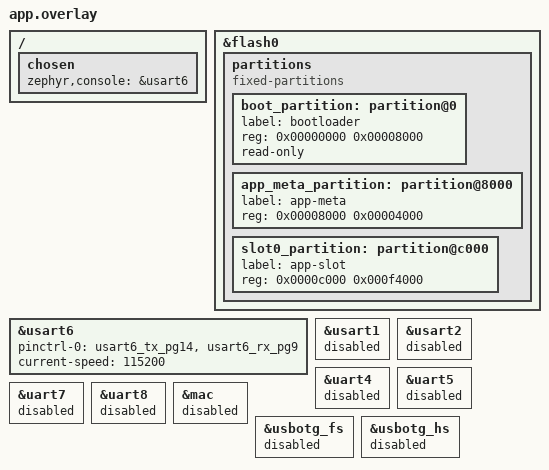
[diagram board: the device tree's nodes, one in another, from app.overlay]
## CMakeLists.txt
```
#
# CMakeLists.txt - Rust demo application on Zephyr (RZDEMO), NUCLEO-F767ZI
#
# Author:  Sandesh Ghimire <sandesh@soccentric.com>
# Date:    2026-11-04
# SRS:     SRS-RZEPHYR-F767 (RZCON-001..004, RZGEN-001..006)
#
# Freestanding Zephyr application built against $ZEPHYR_BASE in the
# stm32-dev-rust-zephyr container, without a west workspace.  The
# application is the Rust crate in this directory (Cargo.toml, src/lib.rs,
# src/app, src/platform, src/protocol), built by Zephyr's Rust module;
# platform/*.c is the small C layer for the driver APIs the Rust bindings do
# not cover yet.  The devicetree files live in boards/.
#   scripts/build.sh [clean]
#

cmake_minimum_required(VERSION 3.20.0)

set(BOARD nucleo_f767zi)
set(DTC_OVERLAY_FILE "${CMAKE_CURRENT_SOURCE_DIR}/boards/nucleo_f767zi.overlay")

# RZCON-002: Zephyr's Rust module is not part of the image's west filter, so
# add it explicitly (docker/Dockerfile installs it).
if(NOT DEFINED ENV{ZEPHYR_RUST_MODULE})
    message(FATAL_ERROR "ZEPHYR_RUST_MODULE is not set; build in the stm32-dev-rust-zephyr container")
endif()
list(APPEND ZEPHYR_EXTRA_MODULES "$ENV{ZEPHYR_RUST_MODULE}")

# --- Version and build metadata (RZGEN-002) --------------------------------
file(STRINGS "${CMAKE_CURRENT_SOURCE_DIR}/VERSION" VERSION_LINES)
foreach(_line IN LISTS VERSION_LINES)
    if(_line MATCHES "^VERSION_MAJOR[ \t]*=[ \t]*([0-9]+)")
        set(APP_VERSION_MAJOR "${CMAKE_MATCH_1}")
    elseif(_line MATCHES "^VERSION_MINOR[ \t]*=[ \t]*([0-9]+)")
        set(APP_VERSION_MINOR "${CMAKE_MATCH_1}")
    elseif(_line MATCHES "^PATCHLEVEL[ \t]*=[ \t]*([0-9]+)")
        set(APP_VERSION_PATCH "${CMAKE_MATCH_1}")
    endif()
endforeach()
if(NOT DEFINED APP_VERSION_MAJOR)
    set(APP_VERSION_MAJOR 0)
endif()
if(NOT DEFINED APP_VERSION_MINOR)
    set(APP_VERSION_MINOR 1)
endif()
if(NOT DEFINED APP_VERSION_PATCH)
    set(APP_VERSION_PATCH 0)
endif()
set(APP_VERSION "${APP_VERSION_MAJOR}.${APP_VERSION_MINOR}.${APP_VERSION_PATCH}")
set(APP_FIRMWARE_NAME "rust-zephyr-app")

execute_process(COMMAND git -C "${CMAKE_CURRENT_SOURCE_DIR}" rev-parse HEAD
    OUTPUT_VARIABLE APP_GIT_COMMIT_FULL OUTPUT_STRIP_TRAILING_WHITESPACE ERROR_QUIET)
if(DEFINED ENV{SOURCE_DATE_EPOCH})
    set(APP_BUILD_TIMESTAMP "$ENV{SOURCE_DATE_EPOCH}")
else()
    string(TIMESTAMP APP_BUILD_TIMESTAMP "%s" UTC)
endif()

# The image's Zephyr tree has no .git; its version is recorded in
# /opt/zephyrproject/VERSION by docker/Dockerfile.zephyr.
if(NOT DEFINED BUILD_VERSION AND EXISTS "$ENV{ZEPHYR_BASE}/../VERSION")
    file(STRINGS "$ENV{ZEPHYR_BASE}/../VERSION" BUILD_VERSION LIMIT_COUNT 1)
endif()

find_package(Zephyr REQUIRED HINTS $ENV{ZEPHYR_BASE})
project(rust_zephyr_app LANGUAGES C)

# RZCON-003: the Rust crate (package "rustapp") becomes librustapp.a and
# provides rust_main(), called from the module's main.c.  dt-rust.yaml is a
# local copy of the module's devicetree augments with the STM32 flash
# controller added.
set(DT_AUGMENTS "${CMAKE_CURRENT_SOURCE_DIR}/boards/dt-rust.yaml" CACHE INTERNAL "")
rust_cargo_application()

target_sources(app PRIVATE platform/platform.c platform/debug_log.c)
target_include_directories(app PRIVATE "${CMAKE_CURRENT_SOURCE_DIR}/platform")

# --- Build products (RZGEN-001, RZGEN-002) ----------------------------------
find_package(Python3 COMPONENTS Interpreter REQUIRED)
get_filename_component(_compiler_dir "${CMAKE_C_COMPILER}" DIRECTORY)
find_program(SIZE_TOOL NAMES arm-zephyr-eabi-size arm-none-eabi-size
    HINTS "${_compiler_dir}" REQUIRED)

add_custom_target(rust_zephyr_app_outputs ALL
    COMMAND ${CMAKE_COMMAND} -E copy
            "${CMAKE_BINARY_DIR}/zephyr/zephyr.elf"
            "${CMAKE_BINARY_DIR}/rust-zephyr-app.elf"
    COMMAND ${CMAKE_COMMAND} -E copy
            "${CMAKE_BINARY_DIR}/zephyr/zephyr.bin"
            "${CMAKE_BINARY_DIR}/rust-zephyr-app.bin"
    COMMAND ${CMAKE_COMMAND} -E copy
            "${CMAKE_BINARY_DIR}/zephyr/zephyr.hex"
            "${CMAKE_BINARY_DIR}/rust-zephyr-app.hex"
    COMMAND ${CMAKE_COMMAND} -E copy
            "${CMAKE_BINARY_DIR}/zephyr/zephyr.map"
            "${CMAKE_BINARY_DIR}/rust-zephyr-app.map"
    COMMAND ${Python3_EXECUTABLE} "${CMAKE_CURRENT_SOURCE_DIR}/scripts/mkimage.py"
            --input "${CMAKE_BINARY_DIR}/rust-zephyr-app.bin"
            --output "${CMAKE_BINARY_DIR}/rust-zephyr-app.img"
            --version "${APP_VERSION}"
            --commit "${APP_GIT_COMMIT_FULL}"
            --timestamp "${APP_BUILD_TIMESTAMP}"
            --name "${APP_FIRMWARE_NAME}"
    COMMAND ${Python3_EXECUTABLE} "${CMAKE_CURRENT_SOURCE_DIR}/scripts/check_footprint.py"
            --size-tool "${SIZE_TOOL}"
            --max-flash 131072
            --max-ram 65536
            "${CMAKE_BINARY_DIR}/rust-zephyr-app.elf"
    DEPENDS zephyr_final
    BYPRODUCTS
        "${CMAKE_BINARY_DIR}/rust-zephyr-app.elf"
        "${CMAKE_BINARY_DIR}/rust-zephyr-app.bin"
        "${CMAKE_BINARY_DIR}/rust-zephyr-app.hex"
        "${CMAKE_BINARY_DIR}/rust-zephyr-app.map"
        "${CMAKE_BINARY_DIR}/rust-zephyr-app.img"
    COMMENT "Copying rust-zephyr-app.* and generating the BOOT image file")
```

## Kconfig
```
#
# Kconfig - RZDEMO application options
#
# Author:  Sandesh Ghimire <sandesh@soccentric.com>
# Date:    2026-11-04
# Target:  NUCLEO-F767ZI
# SRS:     RZFN-004 (HLT-004)
#

mainmenu "Rust demo application on Zephyr (RZDEMO)"

config RZDEMO_FAIL_HEALTH
	bool "Force the pending-slot health check to fail"
	default n
	help
	  Build the equivalent of the C demo's DEMO_FAIL_HEALTH option.  A
	  pending slot never confirms, LD3 fast-blinks, and the watchdog is
	  stopped after 10 s so BOOT can count a failed trial and roll back.
	  build.rs exports it to Rust as cfg(CONFIG_RZDEMO_FAIL_HEALTH).

source "Kconfig.zephyr"
```

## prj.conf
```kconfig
# prj.conf - RZDEMO Kconfig
# Author: Sandesh Ghimire <sandesh@soccentric.com>
# SRS:    SRS-RZEPHYR-F767

# RZCON-003: the application is written in Rust (Zephyr's Rust module).
# No allocator: every buffer is static, as in the C demos.
CONFIG_RUST=y

# RZBT-001: run from the bootloader slot at 0x0800C000, 976 KB.
CONFIG_USE_DT_CODE_PARTITION=n
CONFIG_FLASH_LOAD_OFFSET=0xC000
CONFIG_FLASH_LOAD_SIZE=0xF4000

# RZRT-003: 1 kHz kernel tick.
CONFIG_SYS_CLOCK_TICKS_PER_SEC=1000

# RZGEN-003: caches on, as in the C demo.
CONFIG_CACHE_MANAGEMENT=y
CONFIG_ICACHE=y
CONFIG_DCACHE=y

# RZRT-006 / RZSAFE-004: MPU stack guards and assertions.
CONFIG_HW_STACK_PROTECTION=y
CONFIG_ASSERT=y

# RZGEN-006: no warnings in the C part either.
CONFIG_COMPILER_WARNINGS_AS_ERRORS=y

# LEDs, button and USART3.
CONFIG_GPIO=y
CONFIG_SERIAL=y
CONFIG_UART_INTERRUPT_DRIVEN=y
CONFIG_UART_USE_RUNTIME_CONFIGURE=y

# RZCON-005: USART3 carries HWLINK only.  RZDBG-001: console and log output
# go to USART6 instead (chosen zephyr,console in boards/nucleo_f767zi.overlay).
CONFIG_CONSOLE=y
CONFIG_UART_CONSOLE=y
CONFIG_PRINTK=y

# RZDBG-002: deferred logging, so no thread waits on the debug UART;
# RZDBG-003: platform/debug_log.c prints the family line format.
CONFIG_LOG=y
CONFIG_LOG_MODE_DEFERRED=y
CONFIG_LOG_BACKEND_UART=y
CONFIG_LOG_OUTPUT=y
CONFIG_LOG_CUSTOM_FORMAT_SUPPORT=y
CONFIG_LOG_BACKEND_UART_OUTPUT_CUSTOM=y
CONFIG_LOG_DEFAULT_LEVEL=3
CONFIG_LOG_BUFFER_SIZE=1024

# RZGEN-004: fatal errors reset the board.
CONFIG_REBOOT=y

# RZBT-006: Zephyr flash API for the CONFIRMED record.
CONFIG_FLASH=y

# RZRT-004: IWDG through the watchdog API.
CONFIG_WATCHDOG=y

# RZRT-005: stack high-water marks and thread names for Status.
CONFIG_INIT_STACKS=y
CONFIG_THREAD_STACK_INFO=y
CONFIG_THREAD_NAME=y

# rust_main() only starts the threads and returns.
CONFIG_MAIN_STACK_SIZE=4096
CONFIG_BOOT_BANNER=n
```

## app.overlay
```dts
/*
 * app.overlay - NUCLEO-F767ZI flash layout for the project A/B bootloader
 *
 * Author:  Sandesh Ghimire <sandesh@soccentric.com>
 * Date:    2026-11-03
 * Target:  NUCLEO-F767ZI
 * SRS:     ZBT-001, ZBT-006, ZSAFE-001/003
 *
 * The board devicetree describes an MCUboot-style layout.  ZDEMO uses the
 * project bootloader layout instead (SRS-BOOT-F767 section 3):
 *
 *   0x08000000  bootloader, sectors 0-1, 32 KB, read-only
 *   0x08008000  metadata, sector 2, 16 KB
 *   0x0800C000  application slot, sectors 3-11, 976 KB
 *
 * Bank swapping maps either bank at 0x08000000, so the same overlay and
 * image work for slot A and slot B.
 */

/delete-node/ &boot_partition;
/delete-node/ &storage_partition;
/delete-node/ &slot0_partition;
/delete-node/ &slot1_partition;
/delete-node/ &scratch_partition;

&flash0 {
	partitions {
		compatible = "fixed-partitions";
		#address-cells = <1>;
		#size-cells = <1>;

		boot_partition: partition@0 {
			label = "bootloader";
			reg = <0x00000000 0x00008000>;
			read-only;
		};

		app_meta_partition: partition@8000 {
			label = "app-meta";
			reg = <0x00008000 0x00004000>;
		};

		slot0_partition: partition@c000 {
			label = "app-slot";
			reg = <0x0000c000 0x000f4000>;
		};
	};
};

/* RZDBG-001: console and log output on USART6 (PG14 = Arduino D1 TX,
 * PG9 = D0 RX), 115200 8N1.  HWLINK keeps USART3 to itself. */
/ {
	chosen {
		zephyr,console = &usart6;
	};
};

&usart6 {
	pinctrl-0 = <&usart6_tx_pg14 &usart6_rx_pg9>;
	pinctrl-names = "default";
	current-speed = <115200>;
	status = "okay";
};

/* ZSAFE-003: only the LEDs, B1, USART3 (HWLINK) and USART6 (debug) are
 * used. */
&usart1 {
	status = "disabled";
};

&usart2 {
	status = "disabled";
};

&uart4 {
	status = "disabled";
};

&uart5 {
	status = "disabled";
};

&uart7 {
	status = "disabled";
};

&uart8 {
	status = "disabled";
};

&mac {
	status = "disabled";
};

&usbotg_fs {
	status = "disabled";
};

&usbotg_hs {
	status = "disabled";
};
```

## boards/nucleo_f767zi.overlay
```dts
/*
 * nucleo_f767zi.overlay - NUCLEO-F767ZI flash layout for the project A/B bootloader
 *
 * Author:  Sandesh Ghimire <sandesh@soccentric.com>
 * Date:    2026-11-03
 * Target:  NUCLEO-F767ZI
 * SRS:     ZBT-001, ZBT-006, ZSAFE-001/003
 *
 * The board devicetree describes an MCUboot-style layout.  ZDEMO uses the
 * project bootloader layout instead (SRS-BOOT-F767 section 3):
 *
 *   0x08000000  bootloader, sectors 0-1, 32 KB, read-only
 *   0x08008000  metadata, sector 2, 16 KB
 *   0x0800C000  application slot, sectors 3-11, 976 KB
 *
 * Bank swapping maps either bank at 0x08000000, so the same overlay and
 * image work for slot A and slot B.
 */

/delete-node/ &boot_partition;
/delete-node/ &storage_partition;
/delete-node/ &slot0_partition;
/delete-node/ &slot1_partition;
/delete-node/ &scratch_partition;

&flash0 {
	partitions {
		compatible = "fixed-partitions";
		#address-cells = <1>;
		#size-cells = <1>;

		boot_partition: partition@0 {
			label = "bootloader";
			reg = <0x00000000 0x00008000>;
			read-only;
		};

		app_meta_partition: partition@8000 {
			label = "app-meta";
			reg = <0x00008000 0x00004000>;
		};

		slot0_partition: partition@c000 {
			label = "app-slot";
			reg = <0x0000c000 0x000f4000>;
		};
	};
};

/* RZDBG-001: console and log output on USART6 (PG14 = Arduino D1 TX,
 * PG9 = D0 RX), 115200 8N1.  HWLINK keeps USART3 to itself. */
/ {
	chosen {
		zephyr,console = &usart6;
	};
};

&usart6 {
	pinctrl-0 = <&usart6_tx_pg14 &usart6_rx_pg9>;
	pinctrl-names = "default";
	current-speed = <115200>;
	status = "okay";
};

/* ZSAFE-003: only the LEDs, B1, USART3 (HWLINK) and USART6 (debug) are
 * used. */
&usart1 {
	status = "disabled";
};

&usart2 {
	status = "disabled";
};

&uart4 {
	status = "disabled";
};

&uart5 {
	status = "disabled";
};

&uart7 {
	status = "disabled";
};

&uart8 {
	status = "disabled";
};

&mac {
	status = "disabled";
};

&usbotg_fs {
	status = "disabled";
};

&usbotg_hs {
	status = "disabled";
};
```

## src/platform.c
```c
/*
 * platform.c - C platform layer called from the Rust application
 *
 * Author:  Sandesh Ghimire <sandesh@soccentric.com>
 * Date:    2026-11-04
 * Target:  NUCLEO-F767ZI (Zephyr board nucleo_f767zi)
 * SRS:     RZCON-004, RZBT-002, RZBT-006, RZFN-003, RZRT-004, RZGEN-004
 *
 * Driver glue only: the Rust modules in src/ own the application logic.
 * The UART and fatal-error code follow the C Zephyr demo
 * (app-c-zephyr) so both builds behave the same.
 */

#include <soc.h>
#include <string.h>
#include <zephyr/arch/cpu.h>
#include <zephyr/arch/arm/arch.h>
#include <zephyr/device.h>
#include <zephyr/drivers/flash.h>
#include <zephyr/drivers/gpio.h>
#include <zephyr/drivers/uart.h>
#include <zephyr/drivers/watchdog.h>
#include <zephyr/fatal.h>
#include <zephyr/init.h>
#include <zephyr/kernel.h>
#include <zephyr/linker/sections.h>
#include <zephyr/storage/flash_map.h>
#include <zephyr/sys/reboot.h>
#include <zephyr/sys/ring_buffer.h>

#include "platform.h"

BUILD_ASSERT(CONFIG_FLASH_LOAD_OFFSET == 0xC000,
	     "RZBT-001: the application must be linked at 0x0800C000");
BUILD_ASSERT(CONFIG_FLASH_LOAD_SIZE == 0xF4000,
	     "RZBT-001: the application slot is 976 KB");

/* ---------------------------------------------------------------- fault */

#define FAULT_MAGIC      0x4641554CUL /* "FAUL" */
#define FAULT_REASON_MAX 8U           /* startup, the last reason */

enum {
	FAULT_NONE = 0,
	FAULT_HARDFAULT,
	FAULT_MEMMANAGE,
	FAULT_BUSFAULT,
	FAULT_USAGEFAULT,
	FAULT_ASSERT,
	FAULT_STACK_OVERFLOW,
	FAULT_MALLOC_FAILED,
	FAULT_STARTUP
};

struct fault_record {
	uint32_t magic;
	uint32_t boot_id;
	struct plat_fault data;
};

static struct fault_record fault_record __noinit;
static uint32_t fault_boot_id __noinit;

#define FAULT_LED_PORT GPIOB
#define FAULT_LED_PIN  14U

static void fault_copy(char *dst, uint32_t dst_size, const char *src)
{
	uint32_t i = 0U;

	if (src != NULL) {
		while ((i + 1U) < dst_size && src[i] != '\0') {
			dst[i] = src[i];
			i++;
		}
	}
	dst[i] = '\0';
}

static bool fault_valid(void)
{
	return fault_record.magic == FAULT_MAGIC &&
	       fault_record.data.reason <= FAULT_REASON_MAX;
}

void plat_fault_boot_start(void)
{
	fault_boot_id++;
	if (fault_boot_id == 0U) {
		fault_boot_id = 1U;
	}
}

bool plat_fault_get(struct plat_fault *out)
{
	if (!fault_valid()) {
		return false;
	}
	*out = fault_record.data;
	out->task[PLAT_FAULT_TASK_LEN - 1U] = '\0';
	out->file[PLAT_FAULT_FILE_LEN - 1U] = '\0';
	return true;
}

bool plat_fault_is_current_boot(void)
{
	return fault_valid() && fault_record.boot_id == fault_boot_id;
}

bool plat_fault_is_previous_boot(void)
{
	uint32_t previous = fault_boot_id - 1U;

	if (previous == 0U) {
		previous = 0xFFFFFFFFUL;
	}
	return fault_valid() && fault_record.boot_id == previous;
}

void plat_fault_clear(void)
{
	fault_record.magic = 0U;
	__DMB();
}

void plat_fatal(void)
{
	k_panic();
	CODE_UNREACHABLE;
}

static void fault_save(uint32_t reason, uint32_t pc, uint32_t lr, uint32_t psr,
		       const char *task)
{
	/* Invalidate first so a reset in the middle of the copy is not
	 * mistaken for a complete record. */
	fault_record.magic = 0U;
	__DMB();

	fault_record.boot_id = fault_boot_id;
	fault_record.data.reason = reason;
	fault_record.data.cfsr = SCB->CFSR;
	fault_record.data.hfsr = SCB->HFSR;
	fault_record.data.mmfar = SCB->MMFAR;
	fault_record.data.bfar = SCB->BFAR;
	fault_record.data.pc = pc;
	fault_record.data.lr = lr;
	fault_record.data.psr = psr;
	fault_record.data.line = 0U;
	fault_copy(fault_record.data.task, PLAT_FAULT_TASK_LEN, task);
	fault_copy(fault_record.data.file, PLAT_FAULT_FILE_LEN, "zephyr");

	__DMB();
	fault_record.magic = FAULT_MAGIC;
	__DSB();
}

static void fault_led3(bool on)
{
	FAULT_LED_PORT->BSRR = on ? (1UL << FAULT_LED_PIN)
				  : ((1UL << FAULT_LED_PIN) << 16U);
}

static void fault_show_and_reset(void)
{
	__disable_irq();

	/* Register-level LED set-up: this must work from any context. */
	RCC->AHB1ENR |= RCC_AHB1ENR_GPIOBEN;
	__DSB();
	uint32_t moder = FAULT_LED_PORT->MODER;

	moder &= ~(3UL << (FAULT_LED_PIN * 2U));
	moder |= (1UL << (FAULT_LED_PIN * 2U));
	FAULT_LED_PORT->MODER = moder;
	__DSB();

	/* Three short flashes, a pause, repeat; roughly 2 s. */
	for (uint32_t cycle = 0U; cycle < 2U; cycle++) {
		for (uint32_t flash = 0U; flash < 3U; flash++) {
			fault_led3(true);
			k_busy_wait(100U * USEC_PER_MSEC);
			fault_led3(false);
			k_busy_wait(100U * USEC_PER_MSEC);
		}
		k_busy_wait(500U * USEC_PER_MSEC);
	}

	sys_reboot(SYS_REBOOT_COLD);
	for (;;) {
		__NOP();
	}
}

static uint32_t fatal_reason(unsigned int reason)
{
	if (reason >= K_ERR_ARM_MEM_GENERIC &&
	    reason <= K_ERR_ARM_MEM_FP_LAZY_STATE_PRESERVATION) {
		return FAULT_MEMMANAGE;
	}
	if (reason >= K_ERR_ARM_BUS_GENERIC &&
	    reason <= K_ERR_ARM_BUS_FP_LAZY_STATE_PRESERVATION) {
		return FAULT_BUSFAULT;
	}
	if (reason >= K_ERR_ARM_USAGE_GENERIC &&
	    reason <= K_ERR_ARM_USAGE_UNDEFINED_INSTRUCTION) {
		return reason == K_ERR_ARM_USAGE_STACK_OVERFLOW
			       ? FAULT_STACK_OVERFLOW
			       : FAULT_USAGEFAULT;
	}
	if (reason >= K_ERR_ARM_SECURE_GENERIC &&
	    reason <= K_ERR_ARM_SECURE_LAZY_STATE_ERROR) {
		return FAULT_MEMMANAGE;
	}

	if (reason == K_ERR_CPU_EXCEPTION) {
		uint32_t cfsr = SCB->CFSR;

		if ((cfsr & SCB_CFSR_MEMFAULTSR_Msk) != 0U) {
			return FAULT_MEMMANAGE;
		}
		if ((cfsr & SCB_CFSR_BUSFAULTSR_Msk) != 0U) {
			return FAULT_BUSFAULT;
		}
		if ((cfsr & SCB_CFSR_USGFAULTSR_Msk) != 0U) {
			return FAULT_USAGEFAULT;
		}
		return FAULT_HARDFAULT;
	}

	switch (reason) {
	case K_ERR_STACK_CHK_FAIL:
		return FAULT_STACK_OVERFLOW;
	case K_ERR_KERNEL_OOPS:
	case K_ERR_KERNEL_PANIC:
		/* A Rust panic ends in k_panic() through rust_panic_wrap(). */
		return FAULT_ASSERT;
	case K_ERR_SPURIOUS_IRQ:
	default:
		return FAULT_STARTUP;
	}
}

void k_sys_fatal_error_handler(unsigned int reason, const struct arch_esf *esf)
{
	const char *task = "kernel";
	uint32_t pc = 0U;
	uint32_t lr = 0U;
	uint32_t psr = 0U;

	if (!k_is_in_isr()) {
		const char *name = k_thread_name_get(k_current_get());

		if (name != NULL && name[0] != '\0') {
			task = name;
		}
	}
	if (esf != NULL) {
		pc = esf->basic.pc;
		lr = esf->basic.lr;
		psr = esf->basic.xpsr;
	}

	fault_save(fatal_reason(reason), pc, lr, psr, task);
	fault_show_and_reset();
}

/* --------------------------------------------------------------- system */

uint32_t plat_vtor(void)
{
	return SCB->VTOR;
}

void plat_reboot(void)
{
	sys_reboot(SYS_REBOOT_COLD);
	CODE_UNREACHABLE;
}

void plat_dcache_invalidate(uintptr_t addr, uint32_t len)
{
	SCB_InvalidateDCache_by_Addr((void *)addr, (int32_t)len);
}

void plat_thread_name(const char *name)
{
	(void)k_thread_name_set(k_current_get(), name);
}

uint32_t plat_stack_unused(void)
{
	size_t unused = 0U;

	if (k_thread_stack_space_get(k_current_get(), &unused) != 0) {
		return 0U;
	}
	return (uint32_t)unused;
}

/* ------------------------------------------------------------- watchdog */

#define WDT_TIMEOUT_MS 4000U

static const struct device *const wdt = DEVICE_DT_GET(DT_ALIAS(watchdog0));
static bool wdt_installed;

/* RZBT-002: BOOT starts the IWDG with a 4 s timeout.  Feed it from the very
 * first Zephyr initialisation step, before drivers and the scheduler. */
static int wdt_early_feed(void)
{
	IWDG->KR = 0x0000AAAAUL;
	return 0;
}

SYS_INIT(wdt_early_feed, PRE_KERNEL_1, 0);

void plat_wdt_feed(void)
{
	if (device_is_ready(wdt)) {
		(void)wdt_feed(wdt, 0);
	}
}

bool plat_wdt_init(void)
{
	if (!device_is_ready(wdt)) {
		return false;
	}

	/* The IWDG cannot be stopped once BOOT has started it; installing a
	 * timeout re-writes PR/RLR through the key sequence. */
	if (!wdt_installed) {
		struct wdt_timeout_cfg cfg = {
			.window = {
				.min = 0U,
				.max = WDT_TIMEOUT_MS,
			},
			.callback = NULL,
			.flags = WDT_FLAG_RESET_SOC,
		};

		if (wdt_install_timeout(wdt, &cfg) < 0) {
			return false;
		}
		wdt_installed = true;
	}

	if (wdt_setup(wdt, 0U) < 0) {
		return false;
	}

	plat_wdt_feed();
	return true;
}

/* ---------------------------------------------------------- LEDs and B1 */

static const struct gpio_dt_spec leds[3] = {
	GPIO_DT_SPEC_GET(DT_ALIAS(led0), gpios),
	GPIO_DT_SPEC_GET(DT_ALIAS(led1), gpios),
	GPIO_DT_SPEC_GET(DT_ALIAS(led2), gpios),
};
static const struct gpio_dt_spec button = GPIO_DT_SPEC_GET(DT_ALIAS(sw0), gpios);
static struct gpio_callback button_cb;
static K_SEM_DEFINE(button_sem, 0, 1);

static void button_isr(const struct device *port, struct gpio_callback *cb,
		       gpio_port_pins_t pins)
{
	ARG_UNUSED(port);
	ARG_UNUSED(cb);
	ARG_UNUSED(pins);

	k_sem_give(&button_sem);
}

bool plat_gpio_init(void)
{
	for (uint32_t i = 0U; i < ARRAY_SIZE(leds); i++) {
		if (!gpio_is_ready_dt(&leds[i]) ||
		    gpio_pin_configure_dt(&leds[i], GPIO_OUTPUT_INACTIVE) != 0) {
			return false;
		}
	}

	/* B1 is high when pressed and has an external pull-down. */
	if (!gpio_is_ready_dt(&button) ||
	    gpio_pin_configure_dt(&button, GPIO_INPUT | GPIO_PULL_DOWN) != 0) {
		return false;
	}
	gpio_init_callback(&button_cb, button_isr, BIT(button.pin));
	if (gpio_add_callback_dt(&button, &button_cb) != 0 ||
	    gpio_pin_interrupt_configure_dt(&button, GPIO_INT_EDGE_BOTH) != 0) {
		return false;
	}
	return true;
}

void plat_led_set(uint32_t led, bool on)
{
	if (led < ARRAY_SIZE(leds)) {
		(void)gpio_pin_set_dt(&leds[led], on ? 1 : 0);
	}
}

bool plat_button_pressed(void)
{
	return gpio_pin_get_raw(button.port, button.pin) > 0;
}

void plat_button_wait(uint32_t timeout_ms)
{
	(void)k_sem_take(&button_sem, K_MSEC(timeout_ms));
}

/* --------------------------------------------------------------- USART3 */

#define UART_RX_RING_SIZE 4096U
#define UART_TX_MAX       2200U
#define UART_DEFAULT_BAUD 115200U
#define UART_FAST_BAUD    921600U

static const struct device *const uart = DEVICE_DT_GET(DT_NODELABEL(usart3));

RING_BUF_DECLARE(uart_rx_ring, UART_RX_RING_SIZE);

static K_SEM_DEFINE(uart_tx_sem, 0, 1);
static K_SEM_DEFINE(uart_rx_sem, 0, 1);

static uint8_t uart_tx_buf[UART_TX_MAX];
static volatile uint32_t uart_tx_len;
static volatile uint32_t uart_tx_pos;
static volatile bool uart_rx_enabled;
static uint32_t uart_baud = UART_DEFAULT_BAUD;

static void uart_clear_errors(void)
{
	uint32_t isr = USART3->ISR;

	if ((isr & (USART_ISR_ORE | USART_ISR_FE | USART_ISR_NE |
		    USART_ISR_PE)) != 0U) {
		volatile uint32_t dr = USART3->RDR;

		(void)dr;
		USART3->ICR = USART_ICR_ORECF | USART_ICR_FECF |
			      USART_ICR_NCF | USART_ICR_PECF;
	}
}

static void uart_isr(const struct device *dev, void *user_data)
{
	ARG_UNUSED(user_data);

	(void)uart_irq_update(dev);

	uart_clear_errors();

	bool received = false;

	while (uart_irq_rx_ready(dev)) {
		uint8_t chunk[32];
		int got = uart_fifo_read(dev, chunk, sizeof(chunk));

		if (got <= 0) {
			break;
		}
		(void)ring_buf_put(&uart_rx_ring, chunk, (uint32_t)got);
		received = true;
	}
	if (received) {
		k_sem_give(&uart_rx_sem);
	}

	if (uart_irq_tx_ready(dev)) {
		int sent = uart_fifo_fill(dev, &uart_tx_buf[uart_tx_pos],
					  (int)(uart_tx_len - uart_tx_pos));

		if (sent > 0) {
			uart_tx_pos += (uint32_t)sent;
		}
		if (uart_tx_pos >= uart_tx_len) {
			uart_irq_tx_disable(dev);
			k_sem_give(&uart_tx_sem);
		}
	}
}

static void uart_rx_start(void)
{
	ring_buf_reset(&uart_rx_ring);
	uart_irq_rx_enable(uart);
	uart_irq_err_enable(uart);
	uart_rx_enabled = true;
}

bool plat_uart_init(void)
{
	if (!device_is_ready(uart)) {
		return false;
	}

	const struct uart_config cfg = {
		.baudrate = UART_DEFAULT_BAUD,
		.parity = UART_CFG_PARITY_NONE,
		.stop_bits = UART_CFG_STOP_BITS_1,
		.data_bits = UART_CFG_DATA_BITS_8,
		.flow_ctrl = UART_CFG_FLOW_CTRL_NONE,
	};

	if (uart_configure(uart, &cfg) != 0) {
		return false;
	}

	uart_irq_callback_set(uart, uart_isr);
	uart_rx_start();
	uart_baud = UART_DEFAULT_BAUD;
	return true;
}

bool plat_uart_set_baud(uint32_t baud)
{
	if (baud != UART_DEFAULT_BAUD && baud != UART_FAST_BAUD) {
		return false;
	}
	if (baud == uart_baud) {
		return true;
	}

	struct uart_config cfg;
	uint32_t old_baud = uart_baud;

	if (uart_config_get(uart, &cfg) != 0) {
		return false;
	}

	uart_irq_err_disable(uart);
	uart_irq_rx_disable(uart);
	uart_rx_enabled = false;

	cfg.baudrate = baud;
	if (uart_configure(uart, &cfg) != 0) {
		cfg.baudrate = old_baud;
		(void)uart_configure(uart, &cfg);
		uart_rx_start();
		return false;
	}

	uart_baud = baud;
	uart_rx_start();
	return true;
}

uint32_t plat_uart_read(uint8_t *dst, uint32_t max_len)
{
	return ring_buf_get(&uart_rx_ring, dst, max_len);
}

void plat_uart_wait(uint32_t timeout_ms)
{
	if (ring_buf_is_empty(&uart_rx_ring)) {
		(void)k_sem_take(&uart_rx_sem, K_MSEC(timeout_ms));
	}
}

bool plat_uart_rx_running(void)
{
	return uart_rx_enabled && device_is_ready(uart);
}

bool plat_uart_send(const uint8_t *data, uint32_t len, uint32_t timeout_ms)
{
	if (len == 0U || data == NULL) {
		return true;
	}
	if (len > sizeof(uart_tx_buf)) {
		return false;
	}

	/* Drop a stale completion, then hand the frame to the ISR. */
	(void)k_sem_take(&uart_tx_sem, K_NO_WAIT);
	memcpy(uart_tx_buf, data, len);
	uart_tx_len = len;
	uart_tx_pos = 0U;

	/* The STM32 driver raises TX interrupts on TC only, and TC is clear
	 * after BOOT and after every frame (TCCF below), so enabling the IRQ
	 * alone never starts a frame.  Load the first byte here, before the
	 * IRQ is enabled; its completion sets TC and the ISR sends the rest. */
	int primed = uart_fifo_fill(uart, uart_tx_buf, (int)len);

	if (primed > 0) {
		uart_tx_pos = (uint32_t)primed;
	}
	uart_irq_tx_enable(uart);

	if (k_sem_take(&uart_tx_sem, K_MSEC(timeout_ms)) != 0) {
		uart_irq_tx_disable(uart);
		return false;
	}

	/* Wait until the last stop bit has left the shift register, so a reset
	 * right after the reply does not cut it off. */
	uint32_t start = k_uptime_get_32();

	while ((USART3->ISR & USART_ISR_TC) == 0U) {
		if ((k_uptime_get_32() - start) > 10U) {
			break;
		}
	}
	USART3->ICR = USART_ICR_TCCF;

	return true;
}

/* ------------------------------------------------------ CONFIRMED record */

#define META_RUNNING_ADDR    0x08008000UL
#define META_SIZE            0x00004000UL
#define META_CONFIRMED_OFFSET 0x140U
#define META_RECORD_SIZE     32U

BUILD_ASSERT(PARTITION_ADDRESS(app_meta_partition) == META_RUNNING_ADDR,
	     "app_meta_partition must alias the running slot metadata sector");
BUILD_ASSERT(PARTITION_SIZE(app_meta_partition) == META_SIZE,
	     "app_meta_partition must cover exactly one metadata sector");

static const struct device *const flash_dev = PARTITION_DEVICE(app_meta_partition);
static const off_t confirmed_offset =
	PARTITION_OFFSET(app_meta_partition) + META_CONFIRMED_OFFSET;

/* The STM32F7 flash driver flushes the D-cache for erase but not for a
 * write; invalidate the one record before every read. */
static void confirmed_invalidate(void)
{
	SCB_InvalidateDCache_by_Addr((void *)(META_RUNNING_ADDR + META_CONFIRMED_OFFSET),
				     META_RECORD_SIZE);
}

bool plat_confirmed_read(uint8_t *out32)
{
	if (!device_is_ready(flash_dev)) {
		return false;
	}
	confirmed_invalidate();
	return flash_read(flash_dev, confirmed_offset, out32, META_RECORD_SIZE) == 0;
}

bool plat_confirmed_write(const uint8_t *record32)
{
	if (!device_is_ready(flash_dev)) {
		return false;
	}

	uint32_t record[META_RECORD_SIZE / 4U];

	memcpy(record, record32, sizeof(record));
	int rc = flash_write(flash_dev, confirmed_offset, record, sizeof(record));

	confirmed_invalidate();
	return rc == 0;
}
```

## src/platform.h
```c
/*
 * platform.h - C platform layer called from the Rust application
 *
 * Author:  Sandesh Ghimire <sandesh@soccentric.com>
 * Date:    2026-11-04
 * Target:  NUCLEO-F767ZI (Zephyr board nucleo_f767zi)
 * SRS:     RZCON-004, RZBT-002, RZBT-006, RZFN-003, RZRT-004, RZGEN-004
 *
 * Zephyr's Rust module binds the kernel, GPIO and flash APIs.  The UART,
 * watchdog, devicetree partition and fatal-error paths of this application
 * are not covered yet, so this layer wraps them in plain functions with
 * fixed arguments.  src/plat.rs declares the same functions for Rust; keep
 * the two files in step.  No application logic lives here.
 */

#ifndef RZDEMO_PLATFORM_H
#define RZDEMO_PLATFORM_H

#include <stdbool.h>
#include <stdint.h>

#define PLAT_FAULT_TASK_LEN 16U
#define PLAT_FAULT_FILE_LEN 32U

/* Copy of the no-init fault record (same layout as the C demo's). */
struct plat_fault {
	uint32_t reason;
	uint32_t cfsr;
	uint32_t hfsr;
	uint32_t mmfar;
	uint32_t bfar;
	uint32_t pc;
	uint32_t lr;
	uint32_t psr;
	uint32_t line;
	char task[PLAT_FAULT_TASK_LEN];
	char file[PLAT_FAULT_FILE_LEN];
};

/* RZDBG-001: one debug line on USART6; level 'E', 'W', 'I' or 'D'.  The
 * text is copied (at most PLAT_LOG_TEXT_MAX bytes), not NUL-terminated. */
#define PLAT_LOG_TEXT_MAX 120U
void plat_log(uint8_t level, const uint8_t *text, uint32_t len);

/* Fault record (RZGEN-004). */
void plat_fault_boot_start(void);
bool plat_fault_get(struct plat_fault *out);
bool plat_fault_is_current_boot(void);
bool plat_fault_is_previous_boot(void);
void plat_fault_clear(void);
void plat_fatal(void);

/* System. */
uint32_t plat_vtor(void);
void plat_reboot(void);
void plat_dcache_invalidate(uintptr_t addr, uint32_t len);
void plat_thread_name(const char *name);
uint32_t plat_stack_unused(void);

/* IWDG through the watchdog API (RZRT-004). */
bool plat_wdt_init(void);
void plat_wdt_feed(void);

/* LD1..LD3 and B1 from the board devicetree aliases. */
bool plat_gpio_init(void);
void plat_led_set(uint32_t led, bool on);
bool plat_button_pressed(void);
void plat_button_wait(uint32_t timeout_ms);

/* USART3 HWLINK transport (RZFN-003). */
bool plat_uart_init(void);
bool plat_uart_set_baud(uint32_t baud);
uint32_t plat_uart_read(uint8_t *dst, uint32_t max_len);
void plat_uart_wait(uint32_t timeout_ms);
bool plat_uart_rx_running(void);
bool plat_uart_send(const uint8_t *data, uint32_t len, uint32_t timeout_ms);

/* The 32-byte CONFIRMED record in the running slot's metadata sector
 * (RZBT-006).  The offset is fixed here, never passed in. */
bool plat_confirmed_read(uint8_t *out32);
bool plat_confirmed_write(const uint8_t *record32);

#endif /* RZDEMO_PLATFORM_H */
```
